VERSION ""

NS_ :

BS_:

BU_: PowertrainControlModule AtmosphericSensor SafetyRestraintSystem2 Aftertreatment_2_GasOutlet Aftertreatment_2_GasIntake DieselPartFilterControl Turbocharger SafetyRestraintSystem1 CabDisplay2 Aftertreatment_1_GasOutlet Aftertreatment_1_GasIntake OnBoardDataLogger OffBoardDiagnosticTool2 OffBoardDiagnosticTool1 FileServer ParkingBrakeController SeatController2 FanDriveController SteeringColumnUnit CommunicationUnitRadio CommunicationUnitSatellite CommunicationUnitCellular PropulsionBatteryCharger ChassisController2 ChassisController1 EngineValveControl AuxiliaryHeater2 AuxiliaryHeater1 ClutchUnit RampControl InformationSystem1 SuspensionSystemController2 OilSensor VehicleDynamicStability ExhaustEmissionController TransmissionDisplay2 TransmissionDisplay1 ClimateControl2 WaterPumpController RearAxleSteeringController LightingOperatorControl SeatController1 IgnitionController2 IgnitionController1 TirePressureController CabController2 CabController1 PneumaticSystemController SuspensionSystemController1 HydraulicPumpController EnduranceBrakingSystem RetarderExhaustEngine2 OnBoardDiagnosticUnit HeadwayController RetarderExhaustEngine1 CabDisplay1 ManagementComputer VirtualTerminal OffVehicleGateway PowerTakeOffFront HitchControl AuxiliaryValveControl BodyController TractorTrailerBridge1 StarterSystem ElectricalSystem VehicleSecurity VehicleNavigation AerodynamicControl ElectricalChargingSystem ClimateControl1 TripRecorder InstrumentCluster SuspensionDriveAxle2 SuspensionDriveAxle1 SuspensionSteerAxle SteeringController FuelSystem CruiseControl RetarderDriveline RetarderEngine BrakesDriveAxle2 BrakesDriveAxle1 BrakesSystemController BrakesSteerAxle AxleDrive2 AxleDrive1 AxleSteering PowerTakeOff ShiftConsoleSecondary ShiftConsolePrimary Transmission2 Transmission1 Engine2 Engine1
VAL_TABLE_ FMI 22 "Data Drifted Low" 21 "Data Drifted High" 20 "Received Network Data In Error" 0 "Above normal (most severe)" 1 "Below normal (most severe)" 2 "Data erratic" 3 "Voltage above normal" 4 "Voltage below normal" 5 "Current below normal" 6 "Current above normal" 7 "Mechanical system not responding" 8 "Abnormal frequency" 9 "Abnormal update rate" 10 "Abnormal rate of change" 11 "Root cause not known" 12 "Bad intelligent device" 13 "Out of calibration" 14 "Special intstructions" 15 "Above normal (least severe)" 16 "Above normal (moderately severe)" 17 "Below normal (least severe)" 18 "Below normal (moderately severe)" 19 "Received network data in error" 31 "Condition Exists" ;
VAL_TABLE_ TireLocation_MUX 51 "TirePress_33_MUX_51" 50 "TirePress_32_MUX_50" 49 "TirePress_31_MUX_49" 48 "TirePress_30_MUX_48" 35 "TirePress_23_MUX_35" 34 "TirePress_22_MUX_34" 33 "TirePress_21_MUX_33" 32 "TirePress_20_MUX_32" 19 "TirePress_13_MUX_19" 18 "TirePress_12_MUX_18" 17 "TirePress_11_MUX_17" 16 "TirePress_10_MUX_16" 1 "TirePress_01_MUX_1" 0 "TirePress_00_MUX_0" ;

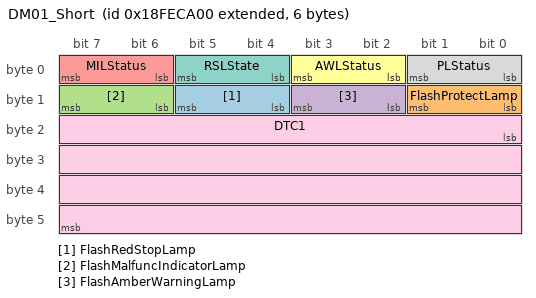
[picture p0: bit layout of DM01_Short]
BO_ 2566834688 DM01_Short: 6 Vector__XXX
 SG_ FlashRedStopLamp : 12|2@1+ (1,0) [0|3] "" Vector__XXX
 SG_ FlashProtectLamp : 8|2@1+ (1,0) [0|3] "" Vector__XXX
 SG_ FlashMalfuncIndicatorLamp : 14|2@1+ (1,0) [0|3] "" Vector__XXX
 SG_ FlashAmberWarningLamp : 10|2@1+ (1,0) [0|3] "" Vector__XXX
 SG_ MILStatus : 6|2@1+ (1,0) [0|3] "" Vector__XXX
 SG_ AWLStatus : 2|2@1+ (1,0) [0|3] "" Vector__XXX
 SG_ RSLState : 4|2@1+ (1,0) [0|3] "" Vector__XXX
 SG_ PLStatus : 0|2@1+ (1,0) [0|3] "" Vector__XXX
 SG_ DTC1 : 16|32@1+ (1,0) [0|4294967295] "" Vector__XXX

CM_ BU_ PowertrainControlModule "Electronic control module in charge of controlling and coordinating the operation of a hybrid propulsion system.";
CM_ BU_ HitchControl "Straight truck hitch (NOT Agricultural hitch – it is in IG 2) ";
CM_ BO_ 2566834688 "Active Diagnostic Trouble Codes
Active Diagnostic Trouble Codes";
CM_ SG_ 2566834688 FlashRedStopLamp "This parameter provides the capability to flash the RSL


00 - Slow Flash (1 Hz, 50 % duty cycle)
01 - Fast Flash (2 Hz or faster, 50% duty cycle)
10 - Reserved
11 - Unavailable / Do Not Flash";
CM_ SG_ 2566834688 FlashProtectLamp "This parameter provides the capability to flash the engine protect lamp


00 - Slow Flash (1 Hz, 50 % duty cycle)
01 - Fast Flash (2 Hz or faster, 50% duty cycle)
10 - Reserved
11 - Unavailable / Do Not Flash";
CM_ SG_ 2566834688 FlashMalfuncIndicatorLamp "This parameter provides the capability to flash the MIL
00 - Slow Flash (1 Hz, 50 % duty cycle)
01 - Fast Flash (2 Hz or faster, 50% duty cycle)
10 - Class C DTC
11 - Unavailable / Do Not Flash
Note:  State 10 is for WWH OBD discriminatory ...";
CM_ SG_ 2566834688 FlashAmberWarningLamp "This parameter provides the capability to flash the AWL

00 - Slow Flash (1 Hz, 50 % duty cycle)
01 - Fast Flash (2 Hz or faster, 50% duty cycle)
10 - Reserved
11 - Unavailable / Do Not Flash";
CM_ SG_ 2566834688 MILStatus "A lamp used to relay only emissions-related trouble code information. This lamp is only illuminated when there is an emission-related trouble code active.
00     Lamp Off
01     Lamp On
10     Short MIL for WWH OBD
11     Not available
Note ...";
CM_ SG_ 2566834688 AWLStatus "This lamp is used to relay trouble code information that is reporting a problem with the vehicle system but the vehicle need not be immediately stopped. 

00     Lamp Off
01     Lamp On
10     Reserved
11     Not available";
CM_ SG_ 2566834688 RSLState "This lamp is used to relay trouble code information that is of a severe enough condition that it warrants stopping the vehicle.

00     Lamp Off
01     Lamp On
10     Reserved
11     Not available";
CM_ SG_ 2566834688 PLStatus "This lamp is used to relay trouble code information that is reporting a problem with a vehicle system that is most probably not electronic subsystem related. For instance, engine coolant temperature is exceeding its prescribed temperature range.
00 ...";
CM_ SG_ 2566834688 DTC1 "Diagnostic Trouble Code";
BA_DEF_  "DBName" STRING ;
BA_DEF_ SG_  "SigType" ENUM  "Default","Range","RangeSigned","ASCII","Discrete","Control","ReferencePGN","DTC","StringDelimiter","StringLength","StringLengthControl","MessageCounter","MessageChecksum";
BA_DEF_ SG_  "GenSigSendType" ENUM  "Cyclic","OnWrite","OnWriteWithRepetition","OnChange","OnChangeWithRepetition","IfActive","IfActiveWithRepetition","NoSigSendType";
BA_DEF_ SG_  "GenSigILSupport" ENUM  "No","Yes";
BA_DEF_ SG_  "GenSigEVName" STRING ;
BA_DEF_ SG_  "SPN" INT 0 524287;
BA_DEF_ BO_  "TpJ1939VarDlc" ENUM  "No","Yes";
BA_DEF_ BO_  "GenMsgILSupport" ENUM  "No","Yes";
BA_DEF_ BO_  "GenMsgRequestable" INT 0 1;
BA_DEF_ BO_  "GenMsgSendType" ENUM  "cyclic","NotUsed","NotUsed","NotUsed","NotUsed","NotUsed","NotUsed","IfActive","noMsgSendType";
BA_DEF_ BO_  "VFrameFormat" ENUM  "StandardCAN","ExtendedCAN","reserved","J1939PG";
BA_DEF_ BU_  "NmStationAddress" INT 0 255;
BA_DEF_ BU_  "NmJ1939IndustryGroup" INT 0 7;
BA_DEF_ BU_  "NmJ1939System" INT 0 127;
BA_DEF_ BU_  "NmJ1939Function" INT 0 255;
BA_DEF_ BU_  "NmJ1939FunctionInstance" INT 0 7;
BA_DEF_ BU_  "NmJ1939ECUInstance" INT 0 3;
BA_DEF_  "SAE_J1939_DA_SpecVersion" STRING ;
BA_DEF_  "SAE_J1939_81_SpecVersion" STRING ;
BA_DEF_  "DatabaseVersion" STRING ;
BA_DEF_  "BusType" STRING ;
BA_DEF_  "ProtocolType" STRING ;
BA_DEF_  "SAE_J1939_75_SpecVersion" STRING ;
BA_DEF_  "SAE_J1939_21_SpecVersion" STRING ;
BA_DEF_  "SAE_J1939_73_SpecVersion" STRING ;
BA_DEF_  "SAE_J1939_71_SpecVersion" STRING ;
BA_DEF_DEF_  "DBName" "";
BA_DEF_DEF_  "SigType" "Default";
BA_DEF_DEF_  "GenSigSendType" "NoSigSendType";
BA_DEF_DEF_  "GenSigILSupport" "Yes";
BA_DEF_DEF_  "GenSigEVName" "Env@Nodename_@Signame";
BA_DEF_DEF_  "SPN" 0;
BA_DEF_DEF_  "TpJ1939VarDlc" "No";
BA_DEF_DEF_  "GenMsgILSupport" "Yes";
BA_DEF_DEF_  "GenMsgRequestable" 1;
BA_DEF_DEF_  "GenMsgSendType" "noMsgSendType";
BA_DEF_DEF_  "VFrameFormat" "J1939PG";
BA_DEF_DEF_  "NmStationAddress" 254;
BA_DEF_DEF_  "NmJ1939IndustryGroup" 0;
BA_DEF_DEF_  "NmJ1939System" 0;
BA_DEF_DEF_  "NmJ1939Function" 0;
BA_DEF_DEF_  "NmJ1939FunctionInstance" 0;
BA_DEF_DEF_  "NmJ1939ECUInstance" 0;
BA_DEF_DEF_  "SAE_J1939_DA_SpecVersion" "";
BA_DEF_DEF_  "SAE_J1939_81_SpecVersion" "";
BA_DEF_DEF_  "DatabaseVersion" "";
BA_DEF_DEF_  "BusType" "";
BA_DEF_DEF_  "ProtocolType" "";
BA_DEF_DEF_  "SAE_J1939_75_SpecVersion" "";
BA_DEF_DEF_  "SAE_J1939_21_SpecVersion" "";
BA_DEF_DEF_  "SAE_J1939_73_SpecVersion" "";
BA_DEF_DEF_  "SAE_J1939_71_SpecVersion" "";
BA_ "SAE_J1939_71_SpecVersion" "2012-10";
BA_ "SAE_J1939_73_SpecVersion" "2012-10";
BA_ "SAE_J1939_21_SpecVersion" "2006-10";
BA_ "SAE_J1939_75_SpecVersion" "2012-05";
BA_ "ProtocolType" "J1939";
BA_ "BusType" "CAN";
BA_ "DatabaseVersion" "8.5";
BA_ "SAE_J1939_81_SpecVersion" "2012-05";
BA_ "SAE_J1939_DA_SpecVersion" "2015-01";
BA_ "DBName" "J1939";
BA_ "NmStationAddress" BU_ PowertrainControlModule 90;
BA_ "NmJ1939Function" BU_ AtmosphericSensor 76;
BA_ "NmStationAddress" BU_ AtmosphericSensor 89;
BA_ "NmJ1939FunctionInstance" BU_ SafetyRestraintSystem2 1;
BA_ "NmJ1939Function" BU_ SafetyRestraintSystem2 132;
BA_ "NmStationAddress" BU_ SafetyRestraintSystem2 88;
BA_ "NmJ1939ECUInstance" BU_ Aftertreatment_2_GasOutlet 1;
BA_ "NmJ1939FunctionInstance" BU_ Aftertreatment_2_GasOutlet 1;
BA_ "NmJ1939Function" BU_ Aftertreatment_2_GasOutlet 68;
BA_ "NmStationAddress" BU_ Aftertreatment_2_GasOutlet 87;
BA_ "NmJ1939FunctionInstance" BU_ Aftertreatment_2_GasIntake 1;
BA_ "NmJ1939Function" BU_ Aftertreatment_2_GasIntake 68;
BA_ "NmStationAddress" BU_ Aftertreatment_2_GasIntake 86;
BA_ "NmJ1939Function" BU_ DieselPartFilterControl 69;
BA_ "NmStationAddress" BU_ DieselPartFilterControl 85;
BA_ "NmJ1939Function" BU_ Turbocharger 133;
BA_ "NmStationAddress" BU_ Turbocharger 2;
BA_ "NmJ1939Function" BU_ SafetyRestraintSystem1 132;
BA_ "NmStationAddress" BU_ SafetyRestraintSystem1 83;
BA_ "NmJ1939FunctionInstance" BU_ CabDisplay2 1;
BA_ "NmJ1939Function" BU_ CabDisplay2 60;
BA_ "NmStationAddress" BU_ CabDisplay2 84;
BA_ "NmJ1939ECUInstance" BU_ Aftertreatment_1_GasOutlet 1;
BA_ "NmJ1939Function" BU_ Aftertreatment_1_GasOutlet 68;
BA_ "NmStationAddress" BU_ Aftertreatment_1_GasOutlet 82;
BA_ "NmJ1939Function" BU_ Aftertreatment_1_GasIntake 68;
BA_ "NmStationAddress" BU_ Aftertreatment_1_GasIntake 81;
BA_ "NmJ1939Function" BU_ OnBoardDataLogger 130;
BA_ "NmStationAddress" BU_ OnBoardDataLogger 251;
BA_ "NmJ1939FunctionInstance" BU_ OffBoardDiagnosticTool2 1;
BA_ "NmJ1939Function" BU_ OffBoardDiagnosticTool2 129;
BA_ "NmStationAddress" BU_ OffBoardDiagnosticTool2 250;
BA_ "NmJ1939Function" BU_ OffBoardDiagnosticTool1 129;
BA_ "NmStationAddress" BU_ OffBoardDiagnosticTool1 249;
BA_ "NmJ1939Function" BU_ FileServer 61;
BA_ "NmStationAddress" BU_ FileServer 248;
BA_ "NmJ1939FunctionInstance" BU_ ParkingBrakeController 1;
BA_ "NmJ1939Function" BU_ ParkingBrakeController 9;
BA_ "NmStationAddress" BU_ ParkingBrakeController 80;
BA_ "NmJ1939FunctionInstance" BU_ SeatController2 1;
BA_ "NmJ1939Function" BU_ SeatController2 40;
BA_ "NmStationAddress" BU_ SeatController2 79;
BA_ "NmJ1939Function" BU_ FanDriveController 58;
BA_ "NmStationAddress" BU_ FanDriveController 78;
BA_ "NmJ1939Function" BU_ SteeringColumnUnit 57;
BA_ "NmStationAddress" BU_ SteeringColumnUnit 77;
BA_ "NmJ1939Function" BU_ CommunicationUnitRadio 56;
BA_ "NmStationAddress" BU_ CommunicationUnitRadio 76;
BA_ "NmJ1939Function" BU_ CommunicationUnitSatellite 55;
BA_ "NmStationAddress" BU_ CommunicationUnitSatellite 75;
BA_ "NmJ1939Function" BU_ CommunicationUnitCellular 54;
BA_ "NmStationAddress" BU_ CommunicationUnitCellular 74;
BA_ "NmJ1939Function" BU_ PropulsionBatteryCharger 31;
BA_ "NmStationAddress" BU_ PropulsionBatteryCharger 73;
BA_ "NmJ1939FunctionInstance" BU_ ChassisController2 1;
BA_ "NmJ1939Function" BU_ ChassisController2 52;
BA_ "NmStationAddress" BU_ ChassisController2 72;
BA_ "NmJ1939Function" BU_ ChassisController1 52;
BA_ "NmStationAddress" BU_ ChassisController1 71;
BA_ "NmJ1939Function" BU_ EngineValveControl 63;
BA_ "NmStationAddress" BU_ EngineValveControl 70;
BA_ "NmJ1939FunctionInstance" BU_ AuxiliaryHeater2 1;
BA_ "NmJ1939Function" BU_ AuxiliaryHeater2 50;
BA_ "NmStationAddress" BU_ AuxiliaryHeater2 69;
BA_ "NmJ1939Function" BU_ AuxiliaryHeater1 50;
BA_ "NmStationAddress" BU_ AuxiliaryHeater1 68;
BA_ "NmJ1939Function" BU_ ClutchUnit 49;
BA_ "NmStationAddress" BU_ ClutchUnit 67;
BA_ "NmJ1939Function" BU_ RampControl 48;
BA_ "NmStationAddress" BU_ RampControl 66;
BA_ "NmJ1939Function" BU_ InformationSystem1 47;
BA_ "NmStationAddress" BU_ InformationSystem1 65;
BA_ "NmJ1939FunctionInstance" BU_ SuspensionSystemController2 1;
BA_ "NmJ1939Function" BU_ SuspensionSystemController2 35;
BA_ "NmStationAddress" BU_ SuspensionSystemController2 64;
BA_ "NmJ1939Function" BU_ OilSensor 46;
BA_ "NmStationAddress" BU_ OilSensor 63;
BA_ "NmJ1939Function" BU_ VehicleDynamicStability 45;
BA_ "NmStationAddress" BU_ VehicleDynamicStability 62;
BA_ "NmJ1939Function" BU_ ExhaustEmissionController 44;
BA_ "NmStationAddress" BU_ ExhaustEmissionController 61;
BA_ "NmJ1939FunctionInstance" BU_ TransmissionDisplay2 1;
BA_ "NmJ1939Function" BU_ TransmissionDisplay2 43;
BA_ "NmStationAddress" BU_ TransmissionDisplay2 60;
BA_ "NmJ1939Function" BU_ TransmissionDisplay1 43;
BA_ "NmStationAddress" BU_ TransmissionDisplay1 59;
BA_ "NmJ1939FunctionInstance" BU_ ClimateControl2 1;
BA_ "NmJ1939Function" BU_ ClimateControl2 21;
BA_ "NmStationAddress" BU_ ClimateControl2 58;
BA_ "NmJ1939Function" BU_ WaterPumpController 42;
BA_ "NmStationAddress" BU_ WaterPumpController 57;
BA_ "NmJ1939FunctionInstance" BU_ RearAxleSteeringController 1;
BA_ "NmJ1939Function" BU_ RearAxleSteeringController 16;
BA_ "NmStationAddress" BU_ RearAxleSteeringController 56;
BA_ "NmJ1939Function" BU_ LightingOperatorControl 41;
BA_ "NmStationAddress" BU_ LightingOperatorControl 55;
BA_ "NmJ1939Function" BU_ SeatController1 40;
BA_ "NmStationAddress" BU_ SeatController1 54;
BA_ "NmJ1939FunctionInstance" BU_ IgnitionController2 1;
BA_ "NmJ1939Function" BU_ IgnitionController2 39;
BA_ "NmStationAddress" BU_ IgnitionController2 53;
BA_ "NmJ1939Function" BU_ IgnitionController1 39;
BA_ "NmStationAddress" BU_ IgnitionController1 52;
BA_ "NmJ1939Function" BU_ TirePressureController 38;
BA_ "NmStationAddress" BU_ TirePressureController 51;
BA_ "NmJ1939FunctionInstance" BU_ CabController2 1;
BA_ "NmJ1939Function" BU_ CabController2 37;
BA_ "NmStationAddress" BU_ CabController2 50;
BA_ "NmJ1939Function" BU_ CabController1 37;
BA_ "NmStationAddress" BU_ CabController1 49;
BA_ "NmJ1939Function" BU_ PneumaticSystemController 36;
BA_ "NmStationAddress" BU_ PneumaticSystemController 48;
BA_ "NmJ1939Function" BU_ SuspensionSystemController1 35;
BA_ "NmStationAddress" BU_ SuspensionSystemController1 47;
BA_ "NmJ1939Function" BU_ HydraulicPumpController 34;
BA_ "NmStationAddress" BU_ HydraulicPumpController 46;
BA_ "NmJ1939Function" BU_ EnduranceBrakingSystem 64;
BA_ "NmStationAddress" BU_ EnduranceBrakingSystem 45;
BA_ "NmJ1939FunctionInstance" BU_ RetarderExhaustEngine2 1;
BA_ "NmJ1939Function" BU_ RetarderExhaustEngine2 12;
BA_ "NmStationAddress" BU_ RetarderExhaustEngine2 44;
BA_ "NmJ1939Function" BU_ OnBoardDiagnosticUnit 62;
BA_ "NmStationAddress" BU_ OnBoardDiagnosticUnit 43;
BA_ "NmJ1939Function" BU_ HeadwayController 32;
BA_ "NmStationAddress" BU_ HeadwayController 42;
BA_ "NmJ1939Function" BU_ RetarderExhaustEngine1 12;
BA_ "NmStationAddress" BU_ RetarderExhaustEngine1 41;
BA_ "NmJ1939Function" BU_ CabDisplay1 60;
BA_ "NmStationAddress" BU_ CabDisplay1 40;
BA_ "NmJ1939Function" BU_ ManagementComputer 30;
BA_ "NmStationAddress" BU_ ManagementComputer 39;
BA_ "NmJ1939Function" BU_ VirtualTerminal 29;
BA_ "NmStationAddress" BU_ VirtualTerminal 38;
BA_ "NmJ1939Function" BU_ OffVehicleGateway 28;
BA_ "NmStationAddress" BU_ OffVehicleGateway 37;
BA_ "NmJ1939Function" BU_ PowerTakeOffFront 27;
BA_ "NmStationAddress" BU_ PowerTakeOffFront 36;
BA_ "NmStationAddress" BU_ HitchControl 35;
BA_ "NmJ1939Function" BU_ AuxiliaryValveControl 129;
BA_ "NmJ1939System" BU_ AuxiliaryValveControl 1;
BA_ "NmJ1939IndustryGroup" BU_ AuxiliaryValveControl 2;
BA_ "NmStationAddress" BU_ AuxiliaryValveControl 34;
BA_ "NmJ1939Function" BU_ BodyController 26;
BA_ "NmStationAddress" BU_ BodyController 33;
BA_ "NmJ1939Function" BU_ TractorTrailerBridge1 25;
BA_ "NmStationAddress" BU_ TractorTrailerBridge1 32;
BA_ "NmJ1939Function" BU_ StarterSystem 59;
BA_ "NmStationAddress" BU_ StarterSystem 31;
BA_ "NmJ1939Function" BU_ ElectricalSystem 67;
BA_ "NmStationAddress" BU_ ElectricalSystem 30;
BA_ "NmJ1939Function" BU_ VehicleSecurity 24;
BA_ "NmStationAddress" BU_ VehicleSecurity 29;
BA_ "NmJ1939Function" BU_ VehicleNavigation 23;
BA_ "NmStationAddress" BU_ VehicleNavigation 28;
BA_ "NmJ1939Function" BU_ AerodynamicControl 22;
BA_ "NmStationAddress" BU_ AerodynamicControl 27;
BA_ "NmJ1939Function" BU_ ElectricalChargingSystem 53;
BA_ "NmStationAddress" BU_ ElectricalChargingSystem 26;
BA_ "NmJ1939Function" BU_ ClimateControl1 21;
BA_ "NmStationAddress" BU_ ClimateControl1 25;
BA_ "NmJ1939Function" BU_ TripRecorder 20;
BA_ "NmStationAddress" BU_ TripRecorder 24;
BA_ "NmJ1939Function" BU_ InstrumentCluster 19;
BA_ "NmStationAddress" BU_ InstrumentCluster 23;
BA_ "NmJ1939FunctionInstance" BU_ SuspensionDriveAxle2 1;
BA_ "NmJ1939Function" BU_ SuspensionDriveAxle2 18;
BA_ "NmStationAddress" BU_ SuspensionDriveAxle2 22;
BA_ "NmJ1939Function" BU_ SuspensionDriveAxle1 18;
BA_ "NmStationAddress" BU_ SuspensionDriveAxle1 21;
BA_ "NmJ1939Function" BU_ SuspensionSteerAxle 17;
BA_ "NmStationAddress" BU_ SuspensionSteerAxle 20;
BA_ "NmJ1939Function" BU_ SteeringController 16;
BA_ "NmStationAddress" BU_ SteeringController 19;
BA_ "NmJ1939Function" BU_ FuelSystem 15;
BA_ "NmStationAddress" BU_ FuelSystem 18;
BA_ "NmJ1939Function" BU_ CruiseControl 14;
BA_ "NmStationAddress" BU_ CruiseControl 17;
BA_ "NmJ1939Function" BU_ RetarderDriveline 13;
BA_ "NmStationAddress" BU_ RetarderDriveline 16;
BA_ "NmJ1939Function" BU_ RetarderEngine 12;
BA_ "NmStationAddress" BU_ RetarderEngine 15;
BA_ "NmJ1939FunctionInstance" BU_ BrakesDriveAxle2 1;
BA_ "NmJ1939Function" BU_ BrakesDriveAxle2 11;
BA_ "NmStationAddress" BU_ BrakesDriveAxle2 14;
BA_ "NmJ1939Function" BU_ BrakesDriveAxle1 11;
BA_ "NmStationAddress" BU_ BrakesDriveAxle1 13;
BA_ "NmJ1939Function" BU_ BrakesSystemController 9;
BA_ "NmStationAddress" BU_ BrakesSystemController 11;
BA_ "NmJ1939Function" BU_ BrakesSteerAxle 10;
BA_ "NmStationAddress" BU_ BrakesSteerAxle 12;
BA_ "NmJ1939FunctionInstance" BU_ AxleDrive2 1;
BA_ "NmJ1939Function" BU_ AxleDrive2 8;
BA_ "NmStationAddress" BU_ AxleDrive2 10;
BA_ "NmJ1939Function" BU_ AxleDrive1 8;
BA_ "NmStationAddress" BU_ AxleDrive1 9;
BA_ "NmJ1939Function" BU_ AxleSteering 7;
BA_ "NmStationAddress" BU_ AxleSteering 8;
BA_ "NmJ1939Function" BU_ PowerTakeOff 6;
BA_ "NmStationAddress" BU_ PowerTakeOff 7;
BA_ "NmJ1939FunctionInstance" BU_ ShiftConsoleSecondary 1;
BA_ "NmJ1939Function" BU_ ShiftConsoleSecondary 5;
BA_ "NmStationAddress" BU_ ShiftConsoleSecondary 6;
BA_ "NmJ1939Function" BU_ ShiftConsolePrimary 5;
BA_ "NmStationAddress" BU_ ShiftConsolePrimary 5;
BA_ "NmJ1939FunctionInstance" BU_ Transmission2 1;
BA_ "NmJ1939Function" BU_ Transmission2 3;
BA_ "NmStationAddress" BU_ Transmission2 4;
BA_ "NmJ1939Function" BU_ Transmission1 3;
BA_ "NmStationAddress" BU_ Transmission1 3;
BA_ "NmJ1939FunctionInstance" BU_ Engine2 1;
BA_ "NmStationAddress" BU_ Engine2 1;
BA_ "NmStationAddress" BU_ Engine1 0;
BA_ "TpJ1939VarDlc" BO_ 2566834688 1;
BA_ "SPN" SG_ 2566834688 FlashRedStopLamp 3039;
BA_ "SigType" SG_ 2566834688 FlashRedStopLamp 5;
BA_ "SPN" SG_ 2566834688 FlashProtectLamp 3041;
BA_ "SigType" SG_ 2566834688 FlashProtectLamp 5;
BA_ "SPN" SG_ 2566834688 FlashMalfuncIndicatorLamp 3038;
BA_ "SigType" SG_ 2566834688 FlashMalfuncIndicatorLamp 5;
BA_ "SPN" SG_ 2566834688 FlashAmberWarningLamp 3040;
BA_ "SigType" SG_ 2566834688 FlashAmberWarningLamp 5;
BA_ "SPN" SG_ 2566834688 MILStatus 1213;
BA_ "SigType" SG_ 2566834688 MILStatus 5;
BA_ "SPN" SG_ 2566834688 AWLStatus 624;
BA_ "SigType" SG_ 2566834688 AWLStatus 5;
BA_ "SPN" SG_ 2566834688 RSLState 623;
BA_ "SigType" SG_ 2566834688 RSLState 4;
BA_ "SPN" SG_ 2566834688 PLStatus 987;
BA_ "SigType" SG_ 2566834688 PLStatus 5;
BA_ "SigType" SG_ 2566834688 DTC1 7;
VAL_ 2566834688 FlashRedStopLamp 3 "Unavailable / Do Not Flash" 2 "Reserved" 1 "Fast Flash" 0 "Slow Flash" ;
VAL_ 2566834688 FlashProtectLamp 3 "Unavailable / Do Not Flash" 2 "Reserved" 1 "Fast Flash" 0 "Slow Flash" ;
VAL_ 2566834688 FlashMalfuncIndicatorLamp 3 "Unavailable / Do Not Flash" 2 "Class C DTC  " 1 "Fast Flash" 0 "Slow Flash" ;
VAL_ 2566834688 FlashAmberWarningLamp 3 "Unavailable / Do Not Flash" 2 "Reserved" 1 "Fast Flash" 0 "Slow Flash" ;
VAL_ 2566834688 MILStatus 3 "Not available" 2 "Short MIL for WWH OBD" 1 "Lamp On" 0 "Lamp Off" ;
VAL_ 2566834688 AWLStatus 3 "Not available" 2 "Reserved" 1 "Lamp On" 0 "Lamp Off" ;
VAL_ 2566834688 RSLState 3 "Not available" 2 "Reserved" 1 "Lamp On" 0 "Lamp Off" ;
VAL_ 2566834688 PLStatus 3 "Not available" 2 "Reserved" 1 "Lamp On" 0 "Lamp Off" ;
